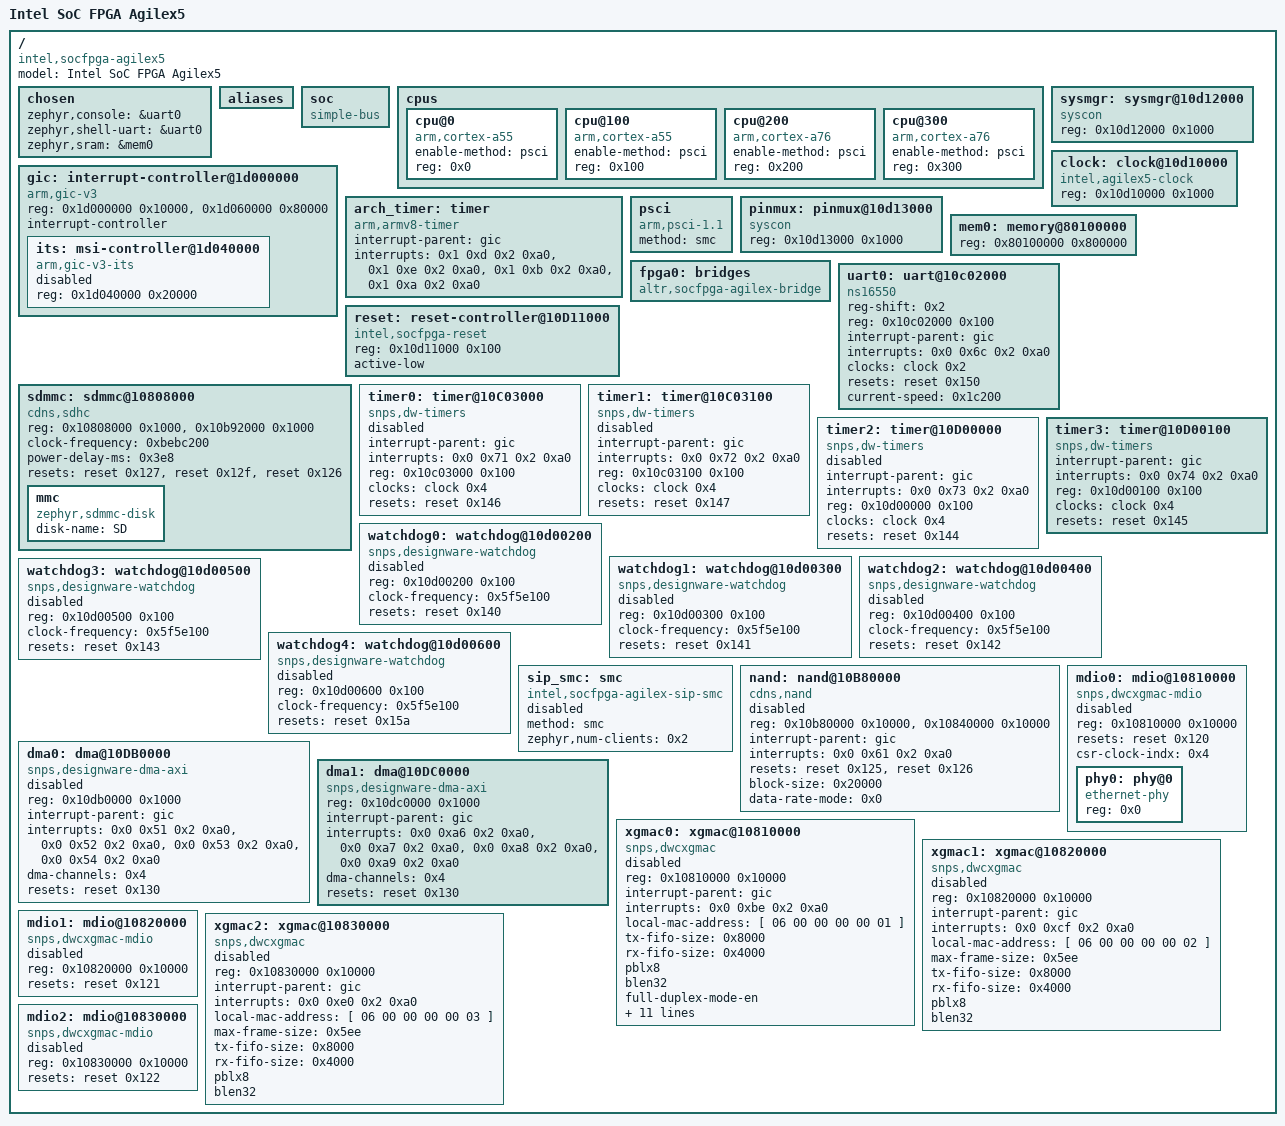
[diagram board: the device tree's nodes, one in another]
/dts-v1/;

/* node '/' defined in zephyr/dts/common/skeleton.dtsi:9 */
/ {
	model = "Intel SoC FPGA Agilex5";     /* in zephyr/boards/intel/socfpga/agilex5_socdk/intel_socfpga_agilex5_socdk.dts:12 */
	compatible = "intel,socfpga-agilex5"; /* in zephyr/boards/intel/socfpga/agilex5_socdk/intel_socfpga_agilex5_socdk.dts:13 */
	#address-cells = < 0x1 >;             /* in zephyr/boards/intel/socfpga/agilex5_socdk/intel_socfpga_agilex5_socdk.dts:14 */
	#size-cells = < 0x1 >;                /* in zephyr/boards/intel/socfpga/agilex5_socdk/intel_socfpga_agilex5_socdk.dts:15 */

	/* node '/chosen' defined in zephyr/dts/common/skeleton.dtsi:13 */
	chosen {
		zephyr,console = &uart0;    /* in zephyr/boards/intel/socfpga/agilex5_socdk/intel_socfpga_agilex5_socdk.dts:18 */
		zephyr,shell-uart = &uart0; /* in zephyr/boards/intel/socfpga/agilex5_socdk/intel_socfpga_agilex5_socdk.dts:19 */
		zephyr,sram = &mem0;        /* in zephyr/boards/intel/socfpga/agilex5_socdk/intel_socfpga_agilex5_socdk.dts:20 */
	};

	/* node '/aliases' defined in zephyr/dts/common/skeleton.dtsi:15 */
	aliases {
	};

	/* node '/soc' defined in zephyr/dts/arm64/armv8-a.dtsi:10 */
	soc {
		#address-cells = < 0x1 >;  /* in zephyr/dts/arm64/armv8-a.dtsi:11 */
		#size-cells = < 0x1 >;     /* in zephyr/dts/arm64/armv8-a.dtsi:12 */
		compatible = "simple-bus"; /* in zephyr/dts/arm64/armv8-a.dtsi:13 */
		ranges;                    /* in zephyr/dts/arm64/armv8-a.dtsi:14 */
	};

	/* node '/cpus' defined in zephyr/dts/arm64/intel/intel_socfpga_agilex5.dtsi:15 */
	cpus {
		#address-cells = < 0x1 >; /* in zephyr/dts/arm64/intel/intel_socfpga_agilex5.dtsi:16 */
		#size-cells = < 0x0 >;    /* in zephyr/dts/arm64/intel/intel_socfpga_agilex5.dtsi:17 */

		/* node '/cpus/cpu@0' defined in zephyr/dts/arm64/intel/intel_socfpga_agilex5.dtsi:19 */
		cpu@0 {
			device_type = "cpu";           /* in zephyr/dts/arm64/intel/intel_socfpga_agilex5.dtsi:20 */
			compatible = "arm,cortex-a55"; /* in zephyr/dts/arm64/intel/intel_socfpga_agilex5.dtsi:21 */
			enable-method = "psci";        /* in zephyr/dts/arm64/intel/intel_socfpga_agilex5.dtsi:22 */
			reg = < 0x0 >;                 /* in zephyr/dts/arm64/intel/intel_socfpga_agilex5.dtsi:23 */
		};

		/* node '/cpus/cpu@100' defined in zephyr/dts/arm64/intel/intel_socfpga_agilex5.dtsi:26 */
		cpu@100 {
			device_type = "cpu";           /* in zephyr/dts/arm64/intel/intel_socfpga_agilex5.dtsi:27 */
			compatible = "arm,cortex-a55"; /* in zephyr/dts/arm64/intel/intel_socfpga_agilex5.dtsi:28 */
			enable-method = "psci";        /* in zephyr/dts/arm64/intel/intel_socfpga_agilex5.dtsi:29 */
			reg = < 0x100 >;               /* in zephyr/dts/arm64/intel/intel_socfpga_agilex5.dtsi:30 */
		};

		/* node '/cpus/cpu@200' defined in zephyr/dts/arm64/intel/intel_socfpga_agilex5.dtsi:33 */
		cpu@200 {
			device_type = "cpu";           /* in zephyr/dts/arm64/intel/intel_socfpga_agilex5.dtsi:34 */
			compatible = "arm,cortex-a76"; /* in zephyr/dts/arm64/intel/intel_socfpga_agilex5.dtsi:35 */
			enable-method = "psci";        /* in zephyr/dts/arm64/intel/intel_socfpga_agilex5.dtsi:36 */
			reg = < 0x200 >;               /* in zephyr/dts/arm64/intel/intel_socfpga_agilex5.dtsi:37 */
		};

		/* node '/cpus/cpu@300' defined in zephyr/dts/arm64/intel/intel_socfpga_agilex5.dtsi:40 */
		cpu@300 {
			device_type = "cpu";           /* in zephyr/dts/arm64/intel/intel_socfpga_agilex5.dtsi:41 */
			compatible = "arm,cortex-a76"; /* in zephyr/dts/arm64/intel/intel_socfpga_agilex5.dtsi:42 */
			enable-method = "psci";        /* in zephyr/dts/arm64/intel/intel_socfpga_agilex5.dtsi:43 */
			reg = < 0x300 >;               /* in zephyr/dts/arm64/intel/intel_socfpga_agilex5.dtsi:44 */
		};
	};

	/* node '/interrupt-controller@1d000000' defined in zephyr/dts/arm64/intel/intel_socfpga_agilex5.dtsi:48 */
	gic: interrupt-controller@1d000000 {
		compatible = "arm,gic-v3",
		             "arm,gic";       /* in zephyr/dts/arm64/intel/intel_socfpga_agilex5.dtsi:49 */
		reg = < 0x1d000000 0x10000 >,
		      < 0x1d060000 0x80000 >; /* in zephyr/dts/arm64/intel/intel_socfpga_agilex5.dtsi:50 */
		interrupt-controller;         /* in zephyr/dts/arm64/intel/intel_socfpga_agilex5.dtsi:52 */
		#interrupt-cells = < 0x4 >;   /* in zephyr/dts/arm64/intel/intel_socfpga_agilex5.dtsi:53 */
		status = "okay";              /* in zephyr/dts/arm64/intel/intel_socfpga_agilex5.dtsi:54 */
		#address-cells = < 0x1 >;     /* in zephyr/dts/arm64/intel/intel_socfpga_agilex5.dtsi:55 */
		#size-cells = < 0x1 >;        /* in zephyr/dts/arm64/intel/intel_socfpga_agilex5.dtsi:56 */
		phandle = < 0x1 >;            /* in zephyr/dts/arm64/intel/intel_socfpga_agilex5.dtsi:67 */

		/* node '/interrupt-controller@1d000000/msi-controller@1d040000' defined in zephyr/dts/arm64/intel/intel_socfpga_agilex5.dtsi:58 */
		its: msi-controller@1d040000 {
			compatible = "arm,gic-v3-its"; /* in zephyr/dts/arm64/intel/intel_socfpga_agilex5.dtsi:59 */
			reg = < 0x1d040000 0x20000 >;  /* in zephyr/dts/arm64/intel/intel_socfpga_agilex5.dtsi:60 */
			status = "disabled";           /* in zephyr/dts/arm64/intel/intel_socfpga_agilex5.dtsi:61 */
		};
	};

	/* node '/timer' defined in zephyr/dts/arm64/intel/intel_socfpga_agilex5.dtsi:65 */
	arch_timer: timer {
		compatible = "arm,armv8-timer";    /* in zephyr/dts/arm64/intel/intel_socfpga_agilex5.dtsi:66 */
		interrupt-parent = < &gic >;       /* in zephyr/dts/arm64/intel/intel_socfpga_agilex5.dtsi:67 */
		interrupts = < 0x1 0xd 0x2 0xa0 >,
		             < 0x1 0xe 0x2 0xa0 >,
		             < 0x1 0xb 0x2 0xa0 >,
		             < 0x1 0xa 0x2 0xa0 >; /* in zephyr/dts/arm64/intel/intel_socfpga_agilex5.dtsi:68 */
	};

	/* node '/sysmgr@10d12000' defined in zephyr/dts/arm64/intel/intel_socfpga_agilex5.dtsi:74 */
	sysmgr: sysmgr@10d12000 {
		compatible = "syscon";       /* in zephyr/dts/arm64/intel/intel_socfpga_agilex5.dtsi:75 */
		reg = < 0x10d12000 0x1000 >; /* in zephyr/dts/arm64/intel/intel_socfpga_agilex5.dtsi:76 */
	};

	/* node '/clock@10d10000' defined in zephyr/dts/arm64/intel/intel_socfpga_agilex5.dtsi:79 */
	clock: clock@10d10000 {
		compatible = "intel,agilex5-clock"; /* in zephyr/dts/arm64/intel/intel_socfpga_agilex5.dtsi:80 */
		reg = < 0x10d10000 0x1000 >;        /* in zephyr/dts/arm64/intel/intel_socfpga_agilex5.dtsi:81 */
		#clock-cells = < 0x1 >;             /* in zephyr/dts/arm64/intel/intel_socfpga_agilex5.dtsi:82 */
		phandle = < 0x2 >;                  /* in zephyr/dts/arm64/intel/intel_socfpga_agilex5.dtsi:112 */
	};

	/* node '/psci' defined in zephyr/dts/arm64/intel/intel_socfpga_agilex5.dtsi:85 */
	psci {
		compatible = "arm,psci-1.1"; /* in zephyr/dts/arm64/intel/intel_socfpga_agilex5.dtsi:86 */
		method = "smc";              /* in zephyr/dts/arm64/intel/intel_socfpga_agilex5.dtsi:87 */
	};

	/* node '/pinmux@10d13000' defined in zephyr/dts/arm64/intel/intel_socfpga_agilex5.dtsi:91 */
	pinmux: pinmux@10d13000 {
		compatible = "syscon";       /* in zephyr/dts/arm64/intel/intel_socfpga_agilex5.dtsi:92 */
		reg = < 0x10d13000 0x1000 >; /* in zephyr/dts/arm64/intel/intel_socfpga_agilex5.dtsi:93 */
	};

	/* node '/memory@80100000' defined in zephyr/dts/arm64/intel/intel_socfpga_agilex5.dtsi:96 */
	mem0: memory@80100000 {
		device_type = "memory";        /* in zephyr/dts/arm64/intel/intel_socfpga_agilex5.dtsi:97 */
		reg = < 0x80100000 0x800000 >; /* in zephyr/dts/arm64/intel/intel_socfpga_agilex5.dtsi:98 */
	};

	/* node '/bridges' defined in zephyr/dts/arm64/intel/intel_socfpga_agilex5.dtsi:101 */
	fpga0: bridges {
		compatible = "altr,socfpga-agilex-bridge"; /* in zephyr/dts/arm64/intel/intel_socfpga_agilex5.dtsi:102 */
	};

	/* node '/uart@10c02000' defined in zephyr/dts/arm64/intel/intel_socfpga_agilex5.dtsi:105 */
	uart0: uart@10c02000 {
		compatible = "ns16550";             /* in zephyr/dts/arm64/intel/intel_socfpga_agilex5.dtsi:106 */
		reg-shift = < 0x2 >;                /* in zephyr/dts/arm64/intel/intel_socfpga_agilex5.dtsi:107 */
		reg = < 0x10c02000 0x100 >;         /* in zephyr/dts/arm64/intel/intel_socfpga_agilex5.dtsi:108 */
		interrupt-parent = < &gic >;        /* in zephyr/dts/arm64/intel/intel_socfpga_agilex5.dtsi:109 */
		interrupts = < 0x0 0x6c 0x2 0xa0 >; /* in zephyr/dts/arm64/intel/intel_socfpga_agilex5.dtsi:110 */
		interrupt-names = "irq_0";          /* in zephyr/dts/arm64/intel/intel_socfpga_agilex5.dtsi:111 */
		clocks = < &clock 0x2 >;            /* in zephyr/dts/arm64/intel/intel_socfpga_agilex5.dtsi:112 */
		resets = < &reset 0x150 >;          /* in zephyr/dts/arm64/intel/intel_socfpga_agilex5.dtsi:113 */
		status = "okay";                    /* in zephyr/boards/intel/socfpga/agilex5_socdk/intel_socfpga_agilex5_socdk.dts:36 */
		current-speed = < 0x1c200 >;        /* in zephyr/boards/intel/socfpga/agilex5_socdk/intel_socfpga_agilex5_socdk.dts:37 */
	};

	/* node '/reset-controller@10D11000' defined in zephyr/dts/arm64/intel/intel_socfpga_agilex5.dtsi:117 */
	reset: reset-controller@10D11000 {
		compatible = "intel,socfpga-reset"; /* in zephyr/dts/arm64/intel/intel_socfpga_agilex5.dtsi:118 */
		reg = < 0x10d11000 0x100 >;         /* in zephyr/dts/arm64/intel/intel_socfpga_agilex5.dtsi:119 */
		active-low;                         /* in zephyr/dts/arm64/intel/intel_socfpga_agilex5.dtsi:120 */
		#reset-cells = < 0x1 >;             /* in zephyr/dts/arm64/intel/intel_socfpga_agilex5.dtsi:121 */
		status = "okay";                    /* in zephyr/dts/arm64/intel/intel_socfpga_agilex5.dtsi:122 */
		phandle = < 0x3 >;                  /* in zephyr/dts/arm64/intel/intel_socfpga_agilex5.dtsi:113 */
	};

	/* node '/sdmmc@10808000' defined in zephyr/dts/arm64/intel/intel_socfpga_agilex5.dtsi:125 */
	sdmmc: sdmmc@10808000 {
		compatible = "cdns,sdhc";        /* in zephyr/dts/arm64/intel/intel_socfpga_agilex5.dtsi:126 */
		reg = < 0x10808000 0x1000 >,
		      < 0x10b92000 0x1000 >;     /* in zephyr/dts/arm64/intel/intel_socfpga_agilex5.dtsi:127 */
		reg-names = "reg_base",
		            "combo_phy";         /* in zephyr/dts/arm64/intel/intel_socfpga_agilex5.dtsi:129 */
		clock-frequency = < 0xbebc200 >; /* in zephyr/dts/arm64/intel/intel_socfpga_agilex5.dtsi:130 */
		power-delay-ms = < 0x3e8 >;      /* in zephyr/dts/arm64/intel/intel_socfpga_agilex5.dtsi:131 */
		resets = < &reset 0x127 >,
		         < &reset 0x12f >,
		         < &reset 0x126 >;       /* in zephyr/dts/arm64/intel/intel_socfpga_agilex5.dtsi:132 */
		status = "okay";                 /* in zephyr/boards/intel/socfpga/agilex5_socdk/intel_socfpga_agilex5_socdk.dts:25 */

		/* node '/sdmmc@10808000/mmc' defined in zephyr/boards/intel/socfpga/agilex5_socdk/intel_socfpga_agilex5_socdk.dts:27 */
		mmc {
			compatible = "zephyr,sdmmc-disk"; /* in zephyr/boards/intel/socfpga/agilex5_socdk/intel_socfpga_agilex5_socdk.dts:29 */
			disk-name = "SD";                 /* in zephyr/boards/intel/socfpga/agilex5_socdk/intel_socfpga_agilex5_socdk.dts:30 */
			status = "okay";                  /* in zephyr/boards/intel/socfpga/agilex5_socdk/intel_socfpga_agilex5_socdk.dts:31 */
		};
	};

	/* node '/timer@10C03000' defined in zephyr/dts/arm64/intel/intel_socfpga_agilex5.dtsi:138 */
	timer0: timer@10C03000 {
		compatible = "snps,dw-timers";      /* in zephyr/dts/arm64/intel/intel_socfpga_agilex5.dtsi:139 */
		interrupt-parent = < &gic >;        /* in zephyr/dts/arm64/intel/intel_socfpga_agilex5.dtsi:140 */
		interrupts = < 0x0 0x71 0x2 0xa0 >; /* in zephyr/dts/arm64/intel/intel_socfpga_agilex5.dtsi:141 */
		reg = < 0x10c03000 0x100 >;         /* in zephyr/dts/arm64/intel/intel_socfpga_agilex5.dtsi:143 */
		clocks = < &clock 0x4 >;            /* in zephyr/dts/arm64/intel/intel_socfpga_agilex5.dtsi:144 */
		resets = < &reset 0x146 >;          /* in zephyr/dts/arm64/intel/intel_socfpga_agilex5.dtsi:145 */
		status = "disabled";                /* in zephyr/dts/arm64/intel/intel_socfpga_agilex5.dtsi:146 */
	};

	/* node '/timer@10C03100' defined in zephyr/dts/arm64/intel/intel_socfpga_agilex5.dtsi:149 */
	timer1: timer@10C03100 {
		compatible = "snps,dw-timers";      /* in zephyr/dts/arm64/intel/intel_socfpga_agilex5.dtsi:150 */
		interrupt-parent = < &gic >;        /* in zephyr/dts/arm64/intel/intel_socfpga_agilex5.dtsi:151 */
		interrupts = < 0x0 0x72 0x2 0xa0 >; /* in zephyr/dts/arm64/intel/intel_socfpga_agilex5.dtsi:152 */
		reg = < 0x10c03100 0x100 >;         /* in zephyr/dts/arm64/intel/intel_socfpga_agilex5.dtsi:154 */
		clocks = < &clock 0x4 >;            /* in zephyr/dts/arm64/intel/intel_socfpga_agilex5.dtsi:155 */
		resets = < &reset 0x147 >;          /* in zephyr/dts/arm64/intel/intel_socfpga_agilex5.dtsi:156 */
		status = "disabled";                /* in zephyr/dts/arm64/intel/intel_socfpga_agilex5.dtsi:157 */
	};

	/* node '/timer@10D00000' defined in zephyr/dts/arm64/intel/intel_socfpga_agilex5.dtsi:160 */
	timer2: timer@10D00000 {
		compatible = "snps,dw-timers";      /* in zephyr/dts/arm64/intel/intel_socfpga_agilex5.dtsi:161 */
		interrupt-parent = < &gic >;        /* in zephyr/dts/arm64/intel/intel_socfpga_agilex5.dtsi:162 */
		interrupts = < 0x0 0x73 0x2 0xa0 >; /* in zephyr/dts/arm64/intel/intel_socfpga_agilex5.dtsi:163 */
		reg = < 0x10d00000 0x100 >;         /* in zephyr/dts/arm64/intel/intel_socfpga_agilex5.dtsi:165 */
		clocks = < &clock 0x4 >;            /* in zephyr/dts/arm64/intel/intel_socfpga_agilex5.dtsi:166 */
		resets = < &reset 0x144 >;          /* in zephyr/dts/arm64/intel/intel_socfpga_agilex5.dtsi:167 */
		status = "disabled";                /* in zephyr/dts/arm64/intel/intel_socfpga_agilex5.dtsi:168 */
	};

	/* node '/timer@10D00100' defined in zephyr/dts/arm64/intel/intel_socfpga_agilex5.dtsi:171 */
	timer3: timer@10D00100 {
		compatible = "snps,dw-timers";      /* in zephyr/dts/arm64/intel/intel_socfpga_agilex5.dtsi:172 */
		interrupt-parent = < &gic >;        /* in zephyr/dts/arm64/intel/intel_socfpga_agilex5.dtsi:173 */
		interrupts = < 0x0 0x74 0x2 0xa0 >; /* in zephyr/dts/arm64/intel/intel_socfpga_agilex5.dtsi:174 */
		reg = < 0x10d00100 0x100 >;         /* in zephyr/dts/arm64/intel/intel_socfpga_agilex5.dtsi:176 */
		clocks = < &clock 0x4 >;            /* in zephyr/dts/arm64/intel/intel_socfpga_agilex5.dtsi:177 */
		resets = < &reset 0x145 >;          /* in zephyr/dts/arm64/intel/intel_socfpga_agilex5.dtsi:178 */
	};

	/* node '/watchdog@10d00200' defined in zephyr/dts/arm64/intel/intel_socfpga_agilex5.dtsi:181 */
	watchdog0: watchdog@10d00200 {
		compatible = "snps,designware-watchdog"; /* in zephyr/dts/arm64/intel/intel_socfpga_agilex5.dtsi:182 */
		reg = < 0x10d00200 0x100 >;              /* in zephyr/dts/arm64/intel/intel_socfpga_agilex5.dtsi:183 */
		clock-frequency = < 0x5f5e100 >;         /* in zephyr/dts/arm64/intel/intel_socfpga_agilex5.dtsi:184 */
		resets = < &reset 0x140 >;               /* in zephyr/dts/arm64/intel/intel_socfpga_agilex5.dtsi:185 */
		status = "disabled";                     /* in zephyr/dts/arm64/intel/intel_socfpga_agilex5.dtsi:186 */
	};

	/* node '/watchdog@10d00300' defined in zephyr/dts/arm64/intel/intel_socfpga_agilex5.dtsi:189 */
	watchdog1: watchdog@10d00300 {
		compatible = "snps,designware-watchdog"; /* in zephyr/dts/arm64/intel/intel_socfpga_agilex5.dtsi:190 */
		reg = < 0x10d00300 0x100 >;              /* in zephyr/dts/arm64/intel/intel_socfpga_agilex5.dtsi:191 */
		clock-frequency = < 0x5f5e100 >;         /* in zephyr/dts/arm64/intel/intel_socfpga_agilex5.dtsi:192 */
		resets = < &reset 0x141 >;               /* in zephyr/dts/arm64/intel/intel_socfpga_agilex5.dtsi:193 */
		status = "disabled";                     /* in zephyr/dts/arm64/intel/intel_socfpga_agilex5.dtsi:194 */
	};

	/* node '/watchdog@10d00400' defined in zephyr/dts/arm64/intel/intel_socfpga_agilex5.dtsi:197 */
	watchdog2: watchdog@10d00400 {
		compatible = "snps,designware-watchdog"; /* in zephyr/dts/arm64/intel/intel_socfpga_agilex5.dtsi:198 */
		reg = < 0x10d00400 0x100 >;              /* in zephyr/dts/arm64/intel/intel_socfpga_agilex5.dtsi:199 */
		clock-frequency = < 0x5f5e100 >;         /* in zephyr/dts/arm64/intel/intel_socfpga_agilex5.dtsi:200 */
		resets = < &reset 0x142 >;               /* in zephyr/dts/arm64/intel/intel_socfpga_agilex5.dtsi:201 */
		status = "disabled";                     /* in zephyr/dts/arm64/intel/intel_socfpga_agilex5.dtsi:202 */
	};

	/* node '/watchdog@10d00500' defined in zephyr/dts/arm64/intel/intel_socfpga_agilex5.dtsi:205 */
	watchdog3: watchdog@10d00500 {
		compatible = "snps,designware-watchdog"; /* in zephyr/dts/arm64/intel/intel_socfpga_agilex5.dtsi:206 */
		reg = < 0x10d00500 0x100 >;              /* in zephyr/dts/arm64/intel/intel_socfpga_agilex5.dtsi:207 */
		clock-frequency = < 0x5f5e100 >;         /* in zephyr/dts/arm64/intel/intel_socfpga_agilex5.dtsi:208 */
		resets = < &reset 0x143 >;               /* in zephyr/dts/arm64/intel/intel_socfpga_agilex5.dtsi:209 */
		status = "disabled";                     /* in zephyr/dts/arm64/intel/intel_socfpga_agilex5.dtsi:210 */
	};

	/* node '/watchdog@10d00600' defined in zephyr/dts/arm64/intel/intel_socfpga_agilex5.dtsi:213 */
	watchdog4: watchdog@10d00600 {
		compatible = "snps,designware-watchdog"; /* in zephyr/dts/arm64/intel/intel_socfpga_agilex5.dtsi:214 */
		reg = < 0x10d00600 0x100 >;              /* in zephyr/dts/arm64/intel/intel_socfpga_agilex5.dtsi:215 */
		clock-frequency = < 0x5f5e100 >;         /* in zephyr/dts/arm64/intel/intel_socfpga_agilex5.dtsi:216 */
		resets = < &reset 0x15a >;               /* in zephyr/dts/arm64/intel/intel_socfpga_agilex5.dtsi:217 */
		status = "disabled";                     /* in zephyr/dts/arm64/intel/intel_socfpga_agilex5.dtsi:218 */
	};

	/* node '/smc' defined in zephyr/dts/arm64/intel/intel_socfpga_agilex5.dtsi:221 */
	sip_smc: smc {
		compatible = "intel,socfpga-agilex-sip-smc"; /* in zephyr/dts/arm64/intel/intel_socfpga_agilex5.dtsi:222 */
		method = "smc";                              /* in zephyr/dts/arm64/intel/intel_socfpga_agilex5.dtsi:223 */
		status = "disabled";                         /* in zephyr/dts/arm64/intel/intel_socfpga_agilex5.dtsi:224 */
		zephyr,num-clients = < 0x2 >;                /* in zephyr/dts/arm64/intel/intel_socfpga_agilex5.dtsi:225 */
	};

	/* node '/nand@10B80000' defined in zephyr/dts/arm64/intel/intel_socfpga_agilex5.dtsi:229 */
	nand: nand@10B80000 {
		compatible = "cdns,nand";           /* in zephyr/dts/arm64/intel/intel_socfpga_agilex5.dtsi:230 */
		reg = < 0x10b80000 0x10000 >,
		      < 0x10840000 0x10000 >;       /* in zephyr/dts/arm64/intel/intel_socfpga_agilex5.dtsi:231 */
		reg-names = "nand_reg",
		            "sdma";                 /* in zephyr/dts/arm64/intel/intel_socfpga_agilex5.dtsi:233 */
		interrupt-parent = < &gic >;        /* in zephyr/dts/arm64/intel/intel_socfpga_agilex5.dtsi:234 */
		interrupts = < 0x0 0x61 0x2 0xa0 >; /* in zephyr/dts/arm64/intel/intel_socfpga_agilex5.dtsi:235 */
		resets = < &reset 0x125 >,
		         < &reset 0x126 >;          /* in zephyr/dts/arm64/intel/intel_socfpga_agilex5.dtsi:236 */
		block-size = < 0x20000 >;           /* in zephyr/dts/arm64/intel/intel_socfpga_agilex5.dtsi:238 */
		data-rate-mode = < 0x0 >;           /* in zephyr/dts/arm64/intel/intel_socfpga_agilex5.dtsi:239 */
		status = "disabled";                /* in zephyr/dts/arm64/intel/intel_socfpga_agilex5.dtsi:240 */
	};

	/* node '/dma@10DB0000' defined in zephyr/dts/arm64/intel/intel_socfpga_agilex5.dtsi:243 */
	dma0: dma@10DB0000 {
		compatible = "snps,designware-dma-axi"; /* in zephyr/dts/arm64/intel/intel_socfpga_agilex5.dtsi:244 */
		#dma-cells = < 0x1 >;                   /* in zephyr/dts/arm64/intel/intel_socfpga_agilex5.dtsi:245 */
		reg = < 0x10db0000 0x1000 >;            /* in zephyr/dts/arm64/intel/intel_socfpga_agilex5.dtsi:246 */
		interrupt-parent = < &gic >;            /* in zephyr/dts/arm64/intel/intel_socfpga_agilex5.dtsi:247 */
		interrupts = < 0x0 0x51 0x2 0xa0 >,
		             < 0x0 0x52 0x2 0xa0 >,
		             < 0x0 0x53 0x2 0xa0 >,
		             < 0x0 0x54 0x2 0xa0 >;     /* in zephyr/dts/arm64/intel/intel_socfpga_agilex5.dtsi:248 */
		dma-channels = < 0x4 >;                 /* in zephyr/dts/arm64/intel/intel_socfpga_agilex5.dtsi:256 */
		resets = < &reset 0x130 >;              /* in zephyr/dts/arm64/intel/intel_socfpga_agilex5.dtsi:257 */
		status = "disabled";                    /* in zephyr/dts/arm64/intel/intel_socfpga_agilex5.dtsi:258 */
	};

	/* node '/dma@10DC0000' defined in zephyr/dts/arm64/intel/intel_socfpga_agilex5.dtsi:261 */
	dma1: dma@10DC0000 {
		compatible = "snps,designware-dma-axi"; /* in zephyr/dts/arm64/intel/intel_socfpga_agilex5.dtsi:262 */
		#dma-cells = < 0x1 >;                   /* in zephyr/dts/arm64/intel/intel_socfpga_agilex5.dtsi:263 */
		reg = < 0x10dc0000 0x1000 >;            /* in zephyr/dts/arm64/intel/intel_socfpga_agilex5.dtsi:264 */
		interrupt-parent = < &gic >;            /* in zephyr/dts/arm64/intel/intel_socfpga_agilex5.dtsi:265 */
		interrupts = < 0x0 0xa6 0x2 0xa0 >,
		             < 0x0 0xa7 0x2 0xa0 >,
		             < 0x0 0xa8 0x2 0xa0 >,
		             < 0x0 0xa9 0x2 0xa0 >;     /* in zephyr/dts/arm64/intel/intel_socfpga_agilex5.dtsi:266 */
		dma-channels = < 0x4 >;                 /* in zephyr/dts/arm64/intel/intel_socfpga_agilex5.dtsi:274 */
		resets = < &reset 0x130 >;              /* in zephyr/dts/arm64/intel/intel_socfpga_agilex5.dtsi:275 */
	};

	/* node '/xgmac@10810000' defined in zephyr/dts/arm64/intel/intel_socfpga_agilex5.dtsi:278 */
	xgmac0: xgmac@10810000 {
		compatible = "snps,dwcxgmac";              /* in zephyr/dts/arm64/intel/intel_socfpga_agilex5.dtsi:279 */
		reg = < 0x10810000 0x10000 >;              /* in zephyr/dts/arm64/intel/intel_socfpga_agilex5.dtsi:280 */
		interrupt-parent = < &gic >;               /* in zephyr/dts/arm64/intel/intel_socfpga_agilex5.dtsi:281 */
		interrupts = < 0x0 0xbe 0x2 0xa0 >;        /* in zephyr/dts/arm64/intel/intel_socfpga_agilex5.dtsi:282 */
		local-mac-address = [ 06 00 00 00 00 01 ]; /* in zephyr/dts/arm64/intel/intel_socfpga_agilex5.dtsi:284 */
		tx-fifo-size = < 0x8000 >;                 /* in zephyr/dts/arm64/intel/intel_socfpga_agilex5.dtsi:286 */
		rx-fifo-size = < 0x4000 >;                 /* in zephyr/dts/arm64/intel/intel_socfpga_agilex5.dtsi:287 */
		pblx8;                                     /* in zephyr/dts/arm64/intel/intel_socfpga_agilex5.dtsi:288 */
		blen32;                                    /* in zephyr/dts/arm64/intel/intel_socfpga_agilex5.dtsi:289 */
		status = "disabled";                       /* in zephyr/dts/arm64/intel/intel_socfpga_agilex5.dtsi:290 */
		full-duplex-mode-en;                       /* in zephyr/boards/intel/socfpga/agilex5_socdk/intel_socfpga_agilex5_socdk.dts:41 */
		num-dma-ch = < 0x1 >;                      /* in zephyr/boards/intel/socfpga/agilex5_socdk/intel_socfpga_agilex5_socdk.dts:42 */
		num-tx-queues = < 0x1 >;                   /* in zephyr/boards/intel/socfpga/agilex5_socdk/intel_socfpga_agilex5_socdk.dts:43 */
		num-rx-queues = < 0x1 >;                   /* in zephyr/boards/intel/socfpga/agilex5_socdk/intel_socfpga_agilex5_socdk.dts:44 */
		num-tc = < 0x1 >;                          /* in zephyr/boards/intel/socfpga/agilex5_socdk/intel_socfpga_agilex5_socdk.dts:45 */
		dma-ch-rdrl = < 0x80 >;                    /* in zephyr/boards/intel/socfpga/agilex5_socdk/intel_socfpga_agilex5_socdk.dts:46 */
		dma-ch-tdrl = < 0x80 >;                    /* in zephyr/boards/intel/socfpga/agilex5_socdk/intel_socfpga_agilex5_socdk.dts:47 */
		max-speed = < 0x3e8 >;                     /* in zephyr/boards/intel/socfpga/agilex5_socdk/intel_socfpga_agilex5_socdk.dts:48 */
		max-frame-size = < 0x233a >;               /* in zephyr/boards/intel/socfpga/agilex5_socdk/intel_socfpga_agilex5_socdk.dts:49 */
		jumbo-pkt-en;                              /* in zephyr/boards/intel/socfpga/agilex5_socdk/intel_socfpga_agilex5_socdk.dts:50 */
		zephyr,random-mac-address;                 /* in zephyr/boards/intel/socfpga/agilex5_socdk/intel_socfpga_agilex5_socdk.dts:51 */
		phy-handle = < &phy0 >;                    /* in zephyr/boards/intel/socfpga/agilex5_socdk/intel_socfpga_agilex5_socdk.dts:52 */
	};

	/* node '/mdio@10810000' defined in zephyr/dts/arm64/intel/intel_socfpga_agilex5.dtsi:293 */
	mdio0: mdio@10810000 {
		#address-cells = < 0x1 >;          /* in zephyr/dts/arm64/intel/intel_socfpga_agilex5.dtsi:294 */
		#size-cells = < 0x0 >;             /* in zephyr/dts/arm64/intel/intel_socfpga_agilex5.dtsi:295 */
		reg = < 0x10810000 0x10000 >;      /* in zephyr/dts/arm64/intel/intel_socfpga_agilex5.dtsi:296 */
		resets = < &reset 0x120 >;         /* in zephyr/dts/arm64/intel/intel_socfpga_agilex5.dtsi:297 */
		compatible = "snps,dwcxgmac-mdio"; /* in zephyr/dts/arm64/intel/intel_socfpga_agilex5.dtsi:298 */
		status = "disabled";               /* in zephyr/dts/arm64/intel/intel_socfpga_agilex5.dtsi:299 */
		csr-clock-indx = < 0x4 >;          /* in zephyr/boards/intel/socfpga/agilex5_socdk/intel_socfpga_agilex5_socdk.dts:56 */

		/* node '/mdio@10810000/phy@0' defined in zephyr/boards/intel/socfpga/agilex5_socdk/intel_socfpga_agilex5_socdk.dts:58 */
		phy0: phy@0 {
			compatible = "ethernet-phy"; /* in zephyr/boards/intel/socfpga/agilex5_socdk/intel_socfpga_agilex5_socdk.dts:59 */
			reg = < 0x0 >;               /* in zephyr/boards/intel/socfpga/agilex5_socdk/intel_socfpga_agilex5_socdk.dts:60 */
			phandle = < 0x4 >;           /* in zephyr/boards/intel/socfpga/agilex5_socdk/intel_socfpga_agilex5_socdk.dts:52 */
		};
	};

	/* node '/xgmac@10820000' defined in zephyr/dts/arm64/intel/intel_socfpga_agilex5.dtsi:302 */
	xgmac1: xgmac@10820000 {
		compatible = "snps,dwcxgmac";              /* in zephyr/dts/arm64/intel/intel_socfpga_agilex5.dtsi:303 */
		reg = < 0x10820000 0x10000 >;              /* in zephyr/dts/arm64/intel/intel_socfpga_agilex5.dtsi:304 */
		interrupt-parent = < &gic >;               /* in zephyr/dts/arm64/intel/intel_socfpga_agilex5.dtsi:305 */
		interrupts = < 0x0 0xcf 0x2 0xa0 >;        /* in zephyr/dts/arm64/intel/intel_socfpga_agilex5.dtsi:306 */
		local-mac-address = [ 06 00 00 00 00 02 ]; /* in zephyr/dts/arm64/intel/intel_socfpga_agilex5.dtsi:308 */
		max-frame-size = < 0x5ee >;                /* in zephyr/dts/arm64/intel/intel_socfpga_agilex5.dtsi:309 */
		tx-fifo-size = < 0x8000 >;                 /* in zephyr/dts/arm64/intel/intel_socfpga_agilex5.dtsi:310 */
		rx-fifo-size = < 0x4000 >;                 /* in zephyr/dts/arm64/intel/intel_socfpga_agilex5.dtsi:311 */
		pblx8;                                     /* in zephyr/dts/arm64/intel/intel_socfpga_agilex5.dtsi:312 */
		blen32;                                    /* in zephyr/dts/arm64/intel/intel_socfpga_agilex5.dtsi:313 */
		status = "disabled";                       /* in zephyr/dts/arm64/intel/intel_socfpga_agilex5.dtsi:314 */
	};

	/* node '/mdio@10820000' defined in zephyr/dts/arm64/intel/intel_socfpga_agilex5.dtsi:317 */
	mdio1: mdio@10820000 {
		#address-cells = < 0x1 >;          /* in zephyr/dts/arm64/intel/intel_socfpga_agilex5.dtsi:318 */
		#size-cells = < 0x0 >;             /* in zephyr/dts/arm64/intel/intel_socfpga_agilex5.dtsi:319 */
		reg = < 0x10820000 0x10000 >;      /* in zephyr/dts/arm64/intel/intel_socfpga_agilex5.dtsi:320 */
		resets = < &reset 0x121 >;         /* in zephyr/dts/arm64/intel/intel_socfpga_agilex5.dtsi:321 */
		compatible = "snps,dwcxgmac-mdio"; /* in zephyr/dts/arm64/intel/intel_socfpga_agilex5.dtsi:322 */
		status = "disabled";               /* in zephyr/dts/arm64/intel/intel_socfpga_agilex5.dtsi:323 */
	};

	/* node '/xgmac@10830000' defined in zephyr/dts/arm64/intel/intel_socfpga_agilex5.dtsi:326 */
	xgmac2: xgmac@10830000 {
		compatible = "snps,dwcxgmac";              /* in zephyr/dts/arm64/intel/intel_socfpga_agilex5.dtsi:327 */
		reg = < 0x10830000 0x10000 >;              /* in zephyr/dts/arm64/intel/intel_socfpga_agilex5.dtsi:328 */
		interrupt-parent = < &gic >;               /* in zephyr/dts/arm64/intel/intel_socfpga_agilex5.dtsi:329 */
		interrupts = < 0x0 0xe0 0x2 0xa0 >;        /* in zephyr/dts/arm64/intel/intel_socfpga_agilex5.dtsi:330 */
		local-mac-address = [ 06 00 00 00 00 03 ]; /* in zephyr/dts/arm64/intel/intel_socfpga_agilex5.dtsi:332 */
		max-frame-size = < 0x5ee >;                /* in zephyr/dts/arm64/intel/intel_socfpga_agilex5.dtsi:333 */
		tx-fifo-size = < 0x8000 >;                 /* in zephyr/dts/arm64/intel/intel_socfpga_agilex5.dtsi:334 */
		rx-fifo-size = < 0x4000 >;                 /* in zephyr/dts/arm64/intel/intel_socfpga_agilex5.dtsi:335 */
		pblx8;                                     /* in zephyr/dts/arm64/intel/intel_socfpga_agilex5.dtsi:336 */
		blen32;                                    /* in zephyr/dts/arm64/intel/intel_socfpga_agilex5.dtsi:337 */
		status = "disabled";                       /* in zephyr/dts/arm64/intel/intel_socfpga_agilex5.dtsi:338 */
	};

	/* node '/mdio@10830000' defined in zephyr/dts/arm64/intel/intel_socfpga_agilex5.dtsi:341 */
	mdio2: mdio@10830000 {
		#address-cells = < 0x1 >;          /* in zephyr/dts/arm64/intel/intel_socfpga_agilex5.dtsi:342 */
		#size-cells = < 0x0 >;             /* in zephyr/dts/arm64/intel/intel_socfpga_agilex5.dtsi:343 */
		reg = < 0x10830000 0x10000 >;      /* in zephyr/dts/arm64/intel/intel_socfpga_agilex5.dtsi:344 */
		resets = < &reset 0x122 >;         /* in zephyr/dts/arm64/intel/intel_socfpga_agilex5.dtsi:345 */
		compatible = "snps,dwcxgmac-mdio"; /* in zephyr/dts/arm64/intel/intel_socfpga_agilex5.dtsi:346 */
		status = "disabled";               /* in zephyr/dts/arm64/intel/intel_socfpga_agilex5.dtsi:347 */
	};
};
